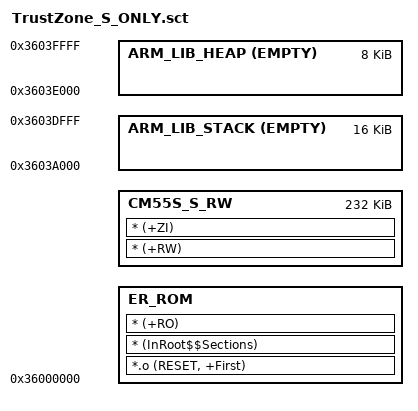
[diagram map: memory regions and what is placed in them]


/*--------------------- Flash Configuration ----------------------------------*/
#define CM55S_S_APP_ROM_BASE     0x36000000 /*BASE_ADDR_SRAM2_ALIAS*/
#define CM55S_S_APP_ROM_SIZE     0x00040000

/*--------------------- Stack / Heap Configuration ---------------------------*/
#define __STACK_S_SIZE    0x00004000
#define __HEAP_S_SIZE     0x00002000
#define CM55S_S_APP_DATASECT_SIZE  (CM55S_S_APP_ROM_SIZE - __STACK_S_SIZE - __HEAP_S_SIZE)
#define __STACK_LIMIT   (CM55S_S_APP_ROM_BASE + CM55S_S_APP_DATASECT_SIZE)
#define __STACK_BASE    (CM55S_S_APP_ROM_BASE + CM55S_S_APP_DATASECT_SIZE + __STACK_S_SIZE)
#define __HEAP_BASE     (CM55S_S_APP_ROM_BASE + CM55S_S_APP_DATASECT_SIZE + __STACK_S_SIZE)
#define __HEAP_LIMIT    (CM55S_S_APP_ROM_BASE + CM55S_S_APP_DATASECT_SIZE + __STACK_S_SIZE + __HEAP_S_SIZE)


LR_ROM1 CM55S_S_APP_ROM_BASE CM55S_S_APP_ROM_SIZE  {                             ; load region size_region
  ER_ROM +0 {                                               ; load address = execution address
   *.o (RESET, +First)
   * (InRoot$$Sections)
   * (+RO)
  }
  CM55S_S_RW  +0  CM55S_S_APP_DATASECT_SIZE { 
   * (+RW)
   * (+ZI)
  }

  ARM_LIB_STACK __STACK_BASE ALIGN 8 EMPTY -__STACK_S_SIZE {
  }
  
  ARM_LIB_HEAP  __HEAP_BASE ALIGN 8 EMPTY __HEAP_S_SIZE  {
  }
}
